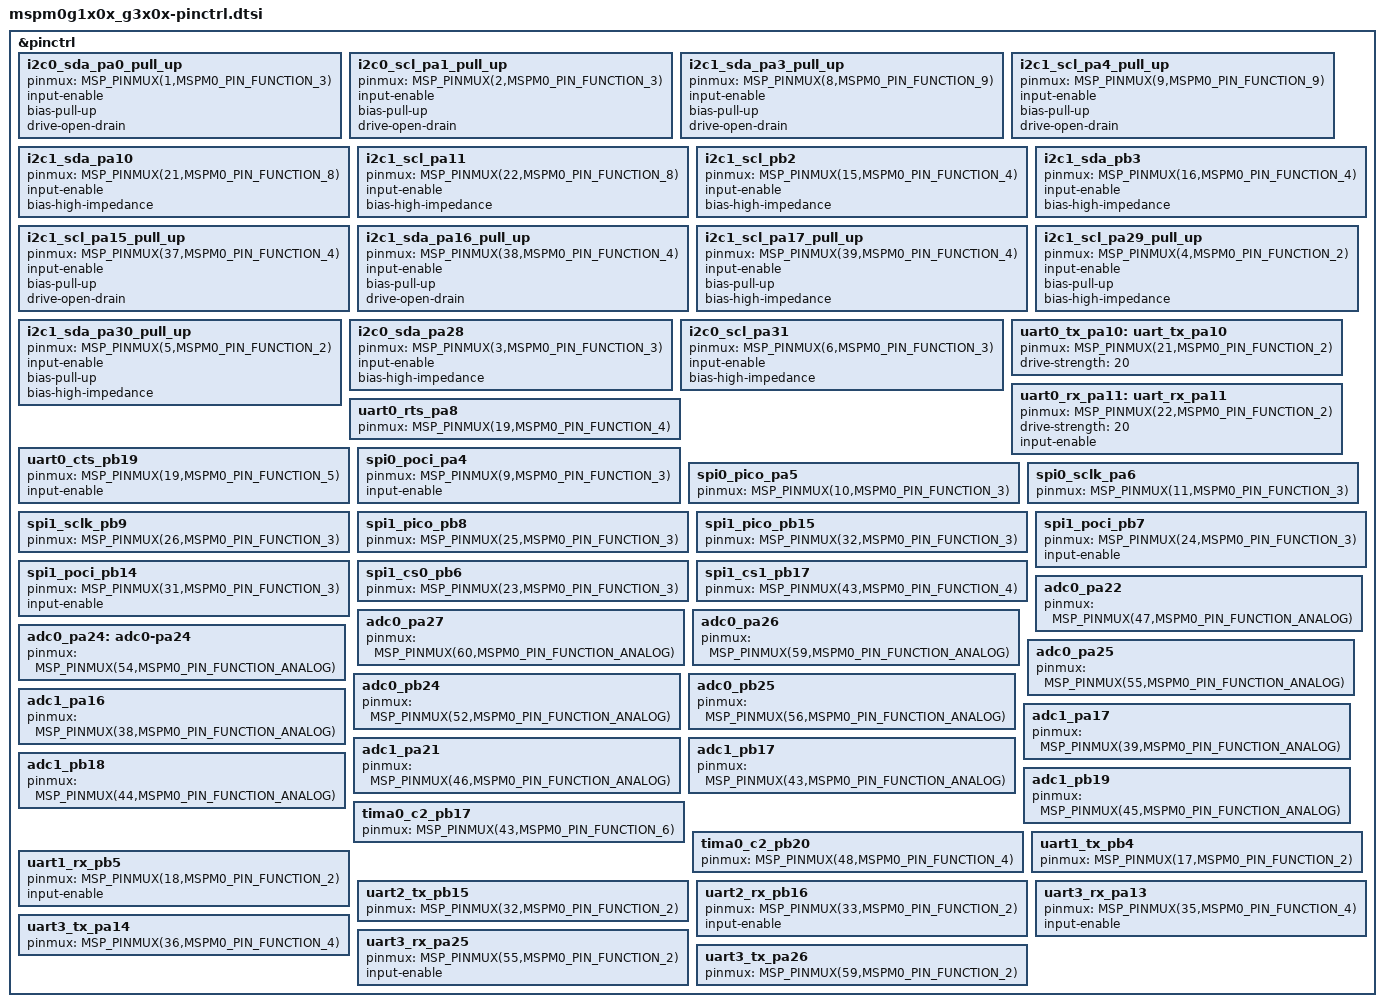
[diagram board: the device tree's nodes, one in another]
	#include <dt-bindings/pinctrl/mspm0-pinctrl.h>

&pinctrl {
	/omit-if-no-ref/ i2c0_sda_pa0_pull_up: i2c0_sda_pa0_pull_up {
		pinmux = <MSP_PINMUX(1,MSPM0_PIN_FUNCTION_3)>;
		input-enable;
		bias-pull-up;
		drive-open-drain;
	};

	/omit-if-no-ref/ i2c0_scl_pa1_pull_up: i2c0_scl_pa1_pull_up {
		pinmux = <MSP_PINMUX(2,MSPM0_PIN_FUNCTION_3)>;
		input-enable;
		bias-pull-up;
		drive-open-drain;
	};

	/omit-if-no-ref/ i2c1_sda_pa3_pull_up: i2c1_sda_pa3_pull_up {
		pinmux = <MSP_PINMUX(8,MSPM0_PIN_FUNCTION_9)>;
		input-enable;
		bias-pull-up;
		drive-open-drain;
	};

	/omit-if-no-ref/ i2c1_scl_pa4_pull_up: i2c1_scl_pa4_pull_up {
		pinmux = <MSP_PINMUX(9,MSPM0_PIN_FUNCTION_9)>;
		input-enable;
		bias-pull-up;
		drive-open-drain;
	};

	/omit-if-no-ref/ i2c1_sda_pa10: i2c1_sda_pa10 {
		pinmux = <MSP_PINMUX(21,MSPM0_PIN_FUNCTION_8)>;
		input-enable;
		bias-high-impedance;
	};

	/omit-if-no-ref/ i2c1_scl_pa11: i2c1_scl_pa11 {
		pinmux = <MSP_PINMUX(22,MSPM0_PIN_FUNCTION_8)>;
		input-enable;
		bias-high-impedance;
	};

	/omit-if-no-ref/ i2c1_scl_pb2: i2c1_scl_pb2 {
		pinmux = <MSP_PINMUX(15,MSPM0_PIN_FUNCTION_4)>;
		input-enable;
		bias-high-impedance;
	};

	/omit-if-no-ref/ i2c1_sda_pb3: i2c1_sda_pb3 {
		pinmux = <MSP_PINMUX(16,MSPM0_PIN_FUNCTION_4)>;
		input-enable;
		bias-high-impedance;
	};

	/omit-if-no-ref/ i2c1_scl_pa15_pull_up: i2c1_scl_pa15_pull_up {
		pinmux = <MSP_PINMUX(37,MSPM0_PIN_FUNCTION_4)>;
		input-enable;
		bias-pull-up;
		drive-open-drain;
	};

	/omit-if-no-ref/ i2c1_sda_pa16_pull_up: i2c1_sda_pa16_pull_up {
		pinmux = <MSP_PINMUX(38,MSPM0_PIN_FUNCTION_4)>;
		input-enable;
		bias-pull-up;
		drive-open-drain;
	};

	/omit-if-no-ref/ i2c1_scl_pa17_pull_up: i2c1_scl_pa17_pull_up {
		pinmux = <MSP_PINMUX(39,MSPM0_PIN_FUNCTION_4)>;
		input-enable;
		bias-pull-up;
		bias-high-impedance;
	};

	/omit-if-no-ref/ i2c1_scl_pa29_pull_up: i2c1_scl_pa29_pull_up {
		pinmux = <MSP_PINMUX(4,MSPM0_PIN_FUNCTION_2)>;
		input-enable;
		bias-pull-up;
		bias-high-impedance;
	};

	/omit-if-no-ref/ i2c1_sda_pa30_pull_up: i2c1_sda_pa30_pull_up {
		pinmux = <MSP_PINMUX(5,MSPM0_PIN_FUNCTION_2)>;
		input-enable;
		bias-pull-up;
		bias-high-impedance;
	};

	/omit-if-no-ref/ i2c0_sda_pa28: i2c0_sda_pa28 {
		pinmux = <MSP_PINMUX(3,MSPM0_PIN_FUNCTION_3)>;
		input-enable;
		bias-high-impedance;
	};

	/omit-if-no-ref/ i2c0_scl_pa31: i2c0_scl_pa31 {
		pinmux = <MSP_PINMUX(6,MSPM0_PIN_FUNCTION_3)>;
		input-enable;
		bias-high-impedance;
	};

	/omit-if-no-ref/ uart0_tx_pa10: uart_tx_pa10 {
		pinmux = <MSP_PINMUX(21,MSPM0_PIN_FUNCTION_2)>;
		drive-strength = <20>;
	};

	/omit-if-no-ref/ uart0_rx_pa11: uart_rx_pa11 {
		pinmux = <MSP_PINMUX(22,MSPM0_PIN_FUNCTION_2)>;
		drive-strength = <20>;
		input-enable;
	};

	/omit-if-no-ref/ uart0_rts_pa8: uart0_rts_pa8 {
		pinmux = <MSP_PINMUX(19,MSPM0_PIN_FUNCTION_4)>;
	};

	/omit-if-no-ref/ uart0_cts_pb19: uart0_cts_pb19 {
		pinmux = <MSP_PINMUX(19,MSPM0_PIN_FUNCTION_5)>;
		input-enable;
	};

	/omit-if-no-ref/ spi0_poci_pa4: spi0_poci_pa4  {
		pinmux = <MSP_PINMUX(9,MSPM0_PIN_FUNCTION_3)>;
		input-enable;
	};

	/omit-if-no-ref/ spi0_pico_pa5: spi0_pico_pa5  {
		pinmux = <MSP_PINMUX(10,MSPM0_PIN_FUNCTION_3)>;
	};

	/omit-if-no-ref/ spi0_sclk_pa6: spi0_sclk_pa6  {
		pinmux = <MSP_PINMUX(11,MSPM0_PIN_FUNCTION_3)>;
	};

	/omit-if-no-ref/ spi1_sclk_pb9: spi1_sclk_pb9 {
		pinmux = <MSP_PINMUX(26,MSPM0_PIN_FUNCTION_3)>;
	};

	/omit-if-no-ref/ spi1_pico_pb8: spi1_pico_pb8 {
		pinmux = <MSP_PINMUX(25,MSPM0_PIN_FUNCTION_3)>;
	};

	/omit-if-no-ref/ spi1_pico_pb15: spi1_pico_pb15 {
		pinmux = <MSP_PINMUX(32,MSPM0_PIN_FUNCTION_3)>;
	};

	/omit-if-no-ref/ spi1_poci_pb7: spi1_poci_pb7 {
		pinmux = <MSP_PINMUX(24,MSPM0_PIN_FUNCTION_3)>;
		input-enable;
	};

	/omit-if-no-ref/ spi1_poci_pb14: spi1_poci_pb14 {
		pinmux = <MSP_PINMUX(31,MSPM0_PIN_FUNCTION_3)>;
		input-enable;
	};

	/omit-if-no-ref/ spi1_cs0_pb6: spi1_cs0_pb6 {
		pinmux = <MSP_PINMUX(23,MSPM0_PIN_FUNCTION_3)>;
	};

	/omit-if-no-ref/ spi1_cs1_pb17: spi1_cs1_pb17 {
		pinmux = <MSP_PINMUX(43,MSPM0_PIN_FUNCTION_4)>;
	};

	/omit-if-no-ref/ adc0_pa22: adc0_pa22 {
		pinmux = <MSP_PINMUX(47,MSPM0_PIN_FUNCTION_ANALOG)>;
	};

	/omit-if-no-ref/ adc0_pa27: adc0_pa27 {
		pinmux = <MSP_PINMUX(60,MSPM0_PIN_FUNCTION_ANALOG)>;
	};

	/omit-if-no-ref/ adc0_pa26: adc0_pa26 {
		pinmux = <MSP_PINMUX(59,MSPM0_PIN_FUNCTION_ANALOG)>;
	};

	/omit-if-no-ref/ adc0_pa24: adc0-pa24 {
		pinmux = <MSP_PINMUX(54,MSPM0_PIN_FUNCTION_ANALOG)>;
	};

	/omit-if-no-ref/ adc0_pa25: adc0_pa25 {
		pinmux = <MSP_PINMUX(55,MSPM0_PIN_FUNCTION_ANALOG)>;
	};

	/omit-if-no-ref/ adc0_pb24: adc0_pb24 {
		pinmux = <MSP_PINMUX(52,MSPM0_PIN_FUNCTION_ANALOG)>;
	};

	/omit-if-no-ref/ adc0_pb25: adc0_pb25 {
		pinmux = <MSP_PINMUX(56,MSPM0_PIN_FUNCTION_ANALOG)>;
	};

	/omit-if-no-ref/ adc1_pa16: adc1_pa16 {
		pinmux = <MSP_PINMUX(38,MSPM0_PIN_FUNCTION_ANALOG)>;
	};

	/omit-if-no-ref/ adc1_pa17: adc1_pa17 {
		pinmux = <MSP_PINMUX(39,MSPM0_PIN_FUNCTION_ANALOG)>;
	};

	/omit-if-no-ref/ adc1_pa21: adc1_pa21 {
		pinmux = <MSP_PINMUX(46,MSPM0_PIN_FUNCTION_ANALOG)>;
	};

	/omit-if-no-ref/ adc1_pb17: adc1_pb17 {
		pinmux = <MSP_PINMUX(43,MSPM0_PIN_FUNCTION_ANALOG)>;
	};

	/omit-if-no-ref/ adc1_pb18: adc1_pb18 {
		pinmux = <MSP_PINMUX(44,MSPM0_PIN_FUNCTION_ANALOG)>;
	};

	/omit-if-no-ref/ adc1_pb19: adc1_pb19 {
		pinmux = <MSP_PINMUX(45,MSPM0_PIN_FUNCTION_ANALOG)>;
	};

	/omit-if-no-ref/ tima0_c2_pb17: tima0_c2_pb17 {
		pinmux = <MSP_PINMUX(43,MSPM0_PIN_FUNCTION_6)>;
	};

	/omit-if-no-ref/ tima0_c2_pb20: tima0_c2_pb20 {
		pinmux = <MSP_PINMUX(48,MSPM0_PIN_FUNCTION_4)>;
	};

	/omit-if-no-ref/ uart1_tx_pb4: uart1_tx_pb4 {
		pinmux = <MSP_PINMUX(17,MSPM0_PIN_FUNCTION_2)>;
	};

	/omit-if-no-ref/ uart1_rx_pb5: uart1_rx_pb5 {
		pinmux = <MSP_PINMUX(18,MSPM0_PIN_FUNCTION_2)>;
		input-enable;
	};

	/omit-if-no-ref/ uart2_tx_pb15: uart2_tx_pb15 {
		pinmux = <MSP_PINMUX(32,MSPM0_PIN_FUNCTION_2)>;
	};

	/omit-if-no-ref/ uart2_rx_pb16: uart2_rx_pb16 {
		pinmux = <MSP_PINMUX(33,MSPM0_PIN_FUNCTION_2)>;
		input-enable;
	};

	/omit-if-no-ref/ uart3_rx_pa13: uart3_rx_pa13 {
		pinmux = <MSP_PINMUX(35,MSPM0_PIN_FUNCTION_4)>;
		input-enable;
	};

	/omit-if-no-ref/ uart3_tx_pa14: uart3_tx_pa14 {
		pinmux = <MSP_PINMUX(36,MSPM0_PIN_FUNCTION_4)>;
	};

	/omit-if-no-ref/ uart3_rx_pa25: uart3_rx_pa25 {
		pinmux = <MSP_PINMUX(55,MSPM0_PIN_FUNCTION_2)>;
		input-enable;
	};

	/omit-if-no-ref/ uart3_tx_pa26: uart3_tx_pa26 {
		pinmux = <MSP_PINMUX(59,MSPM0_PIN_FUNCTION_2)>;
	};
};
